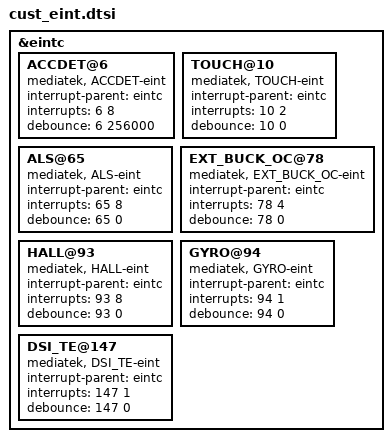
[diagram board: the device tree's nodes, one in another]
/*
 * Generated by MTK SP DrvGen Version 03.13.6 for MT6735M. Copyright MediaTek Inc. (C) 2013.
 * Fri Jul 29 18:19:01 2016
 * Do Not Modify the File.
 */

/*************************
 * EINT DTSI File
*************************/

&eintc {
	ACCDET@6 {
		compatible = "mediatek, ACCDET-eint";
		interrupt-parent = <&eintc>;
		interrupts = <6 8>;
		debounce = <6 256000>;
	};

	TOUCH@10 {
		compatible = "mediatek, TOUCH-eint";
		interrupt-parent = <&eintc>;
		interrupts = <10 2>;
		debounce = <10 0>;
	};

	ALS@65 {
		compatible = "mediatek, ALS-eint";
		interrupt-parent = <&eintc>;
		interrupts = <65 8>;
		debounce = <65 0>;
	};

	EXT_BUCK_OC@78 {
		compatible = "mediatek, EXT_BUCK_OC-eint";
		interrupt-parent = <&eintc>;
		interrupts = <78 4>;
		debounce = <78 0>;
	};

	HALL@93 {
		compatible = "mediatek, HALL-eint";
		interrupt-parent = <&eintc>;
		interrupts = <93 8>;
		debounce = <93 0>;
	};

	GYRO@94 {
		compatible = "mediatek, GYRO-eint";
		interrupt-parent = <&eintc>;
		interrupts = <94 1>;
		debounce = <94 0>;
	};

	DSI_TE@147 {
		compatible = "mediatek, DSI_TE-eint";
		interrupt-parent = <&eintc>;
		interrupts = <147 1>;
		debounce = <147 0>;
	};

};
